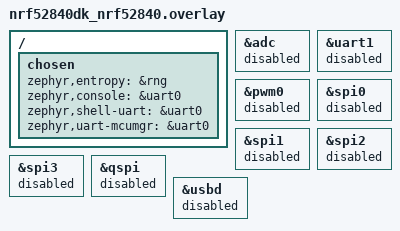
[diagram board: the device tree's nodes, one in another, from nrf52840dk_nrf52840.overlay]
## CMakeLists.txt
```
# SPDX-License-Identifier: Apache-2.0

cmake_minimum_required(VERSION 3.20.0)

find_package(Zephyr REQUIRED HINTS $ENV{ZEPHYR_BASE})

project(sensorConnect)

FILE(GLOB app_sources src/*c)
# APP START
target_sources(app PRIVATE ${app_sources})
```

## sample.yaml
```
sample:
  name: sensorConnect Sample
  description: Test OpenThread Command Line Interface.
tests:
  sample.basic.sensorConnect:
    tags: LED gpio
    filter: dt_enabled_alias_with_parent_compat("led0", "gpio-leds")
    depends_on: gpio
    harness: led
    integration_platforms:
      - frdm_k64f
  sample.openthread.cli:
    build_only: true
    platform_allow: >
      nrf5340dk_nrf5340_cpuapp nrf5340dk_nrf5340_cpuapp_ns nrf52840dk_nrf52840 nrf21540dk_nrf52840
    tags: ci_build
    extra_args: OVERLAY_CONFIG=overlay-ci.conf;overlay-multiprotocol.conf;overlay-tcp.conf
    integration_platforms:
      - nrf5340dk_nrf5340_cpuapp
      - nrf5340dk_nrf5340_cpuapp_ns
      - nrf52840dk_nrf52840
      - nrf21540dk_nrf52840
  sample.openthread.cli_nrf52833:
    build_only: true
    platform_allow: nrf52833dk_nrf52833
    tags: ci_build
    extra_args: OVERLAY_CONFIG=overlay-ci.conf
    integration_platforms:
      - nrf52833dk_nrf52833
  sample.openthread.cli.thread_1_1:
    build_only: true
    platform_allow: >
      nrf5340dk_nrf5340_cpuapp nrf5340dk_nrf5340_cpuapp_ns nrf52840dk_nrf52840 nrf21540dk_nrf52840
    tags: ci_build
    extra_args: >
      CONFIG_OPENTHREAD_THREAD_VERSION_1_1=y
      OVERLAY_CONFIG=overlay-ci.conf;overlay-multiprotocol.conf
    integration_platforms:
      - nrf5340dk_nrf5340_cpuapp
      - nrf5340dk_nrf5340_cpuapp_ns
      - nrf52840dk_nrf52840
      - nrf21540dk_nrf52840
  sample.openthread.cli.usb:
    build_only: true
    platform_allow: >
      nrf5340dk_nrf5340_cpuapp nrf5340dk_nrf5340_cpuapp_ns nrf52840dk_nrf52840
      nrf52840dongle_nrf52840 nrf21540dk_nrf52840
    tags: ci_build
    extra_args: >
      OVERLAY_CONFIG=overlay-usb.conf;overlay-ci.conf;overlay-multiprotocol.conf;overlay-tcp.conf
      DTC_OVERLAY_FILE=usb.overlay
    integration_platforms:
      - nrf5340dk_nrf5340_cpuapp
      - nrf5340dk_nrf5340_cpuapp_ns
      - nrf52840dk_nrf52840
      - nrf52840dongle_nrf52840
      - nrf21540dk_nrf52840
  sample.openthread.cli.low_power:
    build_only: true
    platform_allow: >
      nrf5340dk_nrf5340_cpuapp nrf5340dk_nrf5340_cpuapp_ns nrf52840dk_nrf52840 nrf21540dk_nrf52840
    tags: ci_build
    extra_args: OVERLAY_CONFIG=overlay-ci.conf;overlay-low_power.conf
                DTC_OVERLAY_FILE=low_power.overlay
    integration_platforms:
      - nrf5340dk_nrf5340_cpuapp
      - nrf5340dk_nrf5340_cpuapp_ns
      - nrf52840dk_nrf52840
      - nrf21540dk_nrf52840
  # Build integration regression protection.
  sample.nrf_security.openthread.integration:
    build_only: true
    extra_args: CONFIG_NRF_SECURITY=y
    platform_allow: nrf5340dk_nrf5340_cpuapp_ns nrf52840dk_nrf52840
    integration_platforms:
      - nrf5340dk_nrf5340_cpuapp_ns
      - nrf52840dk_nrf52840
```

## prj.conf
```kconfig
# nRF board library
CONFIG_DK_LIBRARY=y

# Enable OpenThread FTD features set
CONFIG_OPENTHREAD_NORDIC_LIBRARY_FTD=y

# L2 OpenThread enabling
CONFIG_NET_L2_OPENTHREAD=y

# Generic networking options
CONFIG_NETWORKING=y
CONFIG_MBEDTLS_SHA1_C=n
CONFIG_FPU=y

# Network parameter
CONFIG_OPENTHREAD_MANUAL_START=n
CONFIG_OPENTHREAD_NETWORK_NAME="WSN-00"
CONFIG_OPENTHREAD_PANID=10026
CONFIG_OPENTHREAD_XPANID="fb:02:00:00:ab:cd:00:00"
CONFIG_OPENTHREAD_NETWORKKEY="00:11:22:33:44:55:66:77:88:99:aa:bb:cc:dd:ee:ff"

CONFIG_OPENTHREAD_JOINER=y
CONFIG_OPENTHREAD_JOINER_AUTOSTART=y
CONFIG_OPENTHREAD_JOINER_PSKD="123456"

# Network shell
CONFIG_SHELL=y
CONFIG_OPENTHREAD_SHELL=y
CONFIG_SHELL_ARGC_MAX=26
CONFIG_SHELL_CMD_BUFF_SIZE=416

CONFIG_GPIO=y

# Enable OpenThread CoAP support API
CONFIG_OPENTHREAD_COAP=y

# Enable I2C
CONFIG_I2C=y

# Enable Console Print for Debugging
CONFIG_CBPRINTF_FP_SUPPORT=y

CONFIG_ENTROPY_GENERATOR=y
CONFIG_TEST_RANDOM_GENERATOR=y

# Enable FSM
CONFIG_SMF=y

# Enable Button Events
CONFIG_EVENTS=y

# Enable RTT logging in console
CONFIG_USE_SEGGER_RTT=y
CONFIG_LOG_BACKEND_RTT=y
CONFIG_LOG_BACKEND_UART=n
```

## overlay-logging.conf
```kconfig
#
# Copyright (c) 2021 Nordic Semiconductor
#
# SPDX-License-Identifier: LicenseRef-Nordic-5-Clause
# Enable Zephyr logging
CONFIG_LOG=y

# Use separate thread for logging
CONFIG_LOG_MODE_DEFERRED=y

# Increase max log level to informative
CONFIG_LOG_MAX_LEVEL=3

# Option for configuring log level in this sample
CONFIG_OT_COMMAND_LINE_INTERFACE_LOG_LEVEL_INF=y

# Enable net module logging
# CONFIG_NET_LOG=y
# Option for configuring log level in net config library
# CONFIG_NET_CONFIG_LOG_LEVEL_INF=y

# Option for configuring log level in Zephyr L2 logging
# CONFIG_OPENTHREAD_L2_DEBUG=y
# CONFIG_OPENTHREAD_L2_LOG_LEVEL_DBG=y
# CONFIG_OPENTHREAD_L2_DEBUG_DUMP_15_4=y
# CONFIG_OPENTHREAD_L2_DEBUG_DUMP_IPV6=y

# Enable OpenThread logging
CONFIG_OPENTHREAD_DEBUG=y
# Option for configuring log level in OpenThread
CONFIG_OPENTHREAD_LOG_LEVEL_INFO=y

# Enable RTT logging backend
CONFIG_USE_SEGGER_RTT=y
CONFIG_LOG_BACKEND_RTT=y

# Disable UART logging backend
# CONFIG_LOG_BACKEND_UART=n
CONFIG_SHELL_LOG_BACKEND=n
```

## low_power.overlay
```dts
/*
 * Copyright (c) 2023 Nordic Semiconductor ASA
 *
 * SPDX-License-Identifier: LicenseRef-Nordic-5-Clause
 */

&adc {
	status = "disabled";
};
&uart1 {
	status = "disabled";
};
&pwm0 {
	status = "disabled";
};

&spi0 {
	status = "disabled";
};
&spi1 {
	status = "disabled";
};
&spi2 {
	status = "disabled";
};
&spi3 {
	status = "disabled";
};
&usbd {
	status = "disabled";
};
```

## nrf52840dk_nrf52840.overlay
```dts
/ {
	chosen {
		zephyr,entropy = &rng;
		zephyr,console = &uart0;
		zephyr,shell-uart = &uart0;
		zephyr,uart-mcumgr = &uart0;
	};
};
&adc {
	status = "disabled";
};
&uart1 {
	status = "disabled";
};
&pwm0 {
	status = "disabled";
};
&spi0 {
	status = "disabled";
};
&spi1 {
	status = "disabled";
};
&spi2 {
	status = "disabled";
};
&spi3 {
	status = "disabled";
};
&qspi {
	status = "disabled";
};
&usbd {
	status = "disabled";
};
```

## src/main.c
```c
#include <dk_buttons_and_leds.h>
#include <zephyr/smf.h>
#include <zephyr/net/openthread.h>
#include <openthread/thread.h>
#include <openthread/coap.h>
#include <zephyr/drivers/gpio.h>

#include "sensor_functionality.h"

#define SLEEP_TIME_ONE 1
#define SLEEP_TIME_FIVE 5
#define SLEEP_TIME_TEN 10
#define SLEEP_TIME_THIRTY 30
#define SLEEP_TIME_SIXTY 60
#define SLEEP_TIME_THREE_MIN 180
#define NO_SLEEP_TIME 0

#define NO_ERROR 0

#define NO_BLINKING_LED 5

LOG_MODULE_REGISTER(main, LOG_LEVEL_INF);

/**
 * Boolean for printing read sensor values to the console
 * Change to true to enable
*/
static bool print_values_to_console = false;

/**
 * Modes for the Sensor Station
 * 
 * Measure: 		Start/stop periodic measurement
 * Config_period: 	Change the measurement period of the Sensor Station
 * Calibrate: 		Start/stop the selected calibration mode (only Co2 available)
 * 
*/
static enum sensor_station_mode { 
	MEASURE, 
	CONFIG_PERIOD, 
	CALIBRATE
} station_mode;

/* Variables used for managing modes, LEDs, Buttons and States of the SMF */
static bool mode_switch;

static bool btn2_pressed;
static bool btn3_pressed;
static bool btn4_pressed;

static bool run_calibration;
static bool run_per_measurement;
static bool run_frc;

static bool new_led_state;
static uint8_t blinking_led;

static struct k_work blinking_led_3sec_work;
static struct k_timer blinking_led_timer;

static bool show_idle_state;

/* Functions for Handling LEDs */

/**
 * set_blinking_led() - Sets the selected blinking_led to blinking ON/OFF.
*/
static void set_blinking_led() {

	k_timer_stop(&blinking_led_timer);
	switch(station_mode) {
		case CONFIG_PERIOD:
			switch (measure_period) {
				case SIXTY:
					blinking_led = DK_LED4;
					break;
				case THIRTY:
					blinking_led = DK_LED3;
					break;
				case FIVE:
				default:
					blinking_led = DK_LED1;
			}
			break;

		case CALIBRATE:
			switch (calib_mode) {
				case VOC:
					blinking_led = DK_LED2;
					break;
				case TEMP:
					blinking_led = DK_LED4;
					break;
				case CO2:
				default:
					blinking_led = DK_LED1;
			}
			break;
		case MEASURE:
		default:
			blinking_led = NO_BLINKING_LED; 		
	}
	if(blinking_led != NO_BLINKING_LED) {
		k_timer_start(&blinking_led_timer, K_MSEC(500), K_MSEC(500));
	}
}

/**
 * set_select_led() - Sets the selected blinking_led to blinking ON.
*/
static void set_select_led() {

	k_timer_stop(&blinking_led_timer);
	switch(station_mode) {
		case CONFIG_PERIOD:
			switch (measure_period) {
				case SIXTY:
					blinking_led = DK_LED4;
					break;
				case THIRTY:
					blinking_led = DK_LED3;
					break;
				case FIVE:
				default:
					blinking_led = DK_LED1;
			}
			break;

		case CALIBRATE:
			switch (calib_mode) {
				case VOC:
					blinking_led = DK_LED2;
					break;
				case TEMP:
					blinking_led = DK_LED4;
					break;
				case CO2:
				default:
					blinking_led = DK_LED1;
			}
			break;
		case MEASURE:
		default:
			blinking_led = DK_LED2; 		
	}
	
	dk_set_led_on(blinking_led);
}

/**
 * stop_blinking_led() - Sets the selected blinking_led to blinking OFF.
*/
static void stop_blinking_led() {

	k_timer_stop(&blinking_led_timer);
	dk_set_led_off(blinking_led);
}

static void activate_blinking_3_sec(struct k_work *item)
{
	ARG_UNUSED(item);

	set_blinking_led();
	k_sleep(K_SECONDS(SLEEP_TIME_FIVE));
	stop_blinking_led();
}

/* Expiry function of blinking_led_timer */
static void on_blinking_led_timer_expiry(struct k_timer *timer_id)
{
	static uint8_t val = 1;

	ARG_UNUSED(timer_id);

	dk_set_led(blinking_led, val);
	val = !val;
}

/* Stop function of blinking_led_timer */
static void on_blinking_led_timer_stop(struct k_timer *timer_id)
{
	ARG_UNUSED(timer_id);

	dk_set_led_off(blinking_led);
}


/* Button Handler */
static void on_button_changed(uint32_t button_state, uint32_t has_changed)
{
	uint32_t buttons = button_state & has_changed;
	
	if (buttons & DK_BTN1_MSK) {
		mode_switch = true;
	}
	if (buttons & DK_BTN2_MSK) {
		btn2_pressed = true;
	}
	if (buttons & DK_BTN3_MSK) {
		btn3_pressed = true;
	}
	if (buttons & DK_BTN4_MSK) {
		btn4_pressed = true;
	}

}

/* Forward declaration of helper function*/
static const char* station_mode_to_string(enum sensor_station_mode s_mode);
static bool sleep_interruptable(uint8_t sec, bool is_for_calibration);


/* CoAP functionality */
// VM-IP-ADDRESS
const char *serverIpAddr = "fd56:b1f:f132:2:0:0:10.80.2.239";

void coap_init(void);
void coap_send_data_response_cb(void *p_context, otMessage *p_message, const otMessageInfo *p_message_info, otError result);
void coap_send_data_request(char *message);


/* State Machine Framework */

int32_t smf_sleep_sec = NO_SLEEP_TIME;

/* Forward declaration of state table */
static const struct smf_state states[];

/* States */
enum state { 
	INIT, 
	IDLE, 
	START_MEASUREMENT, 
	STOP_MEASUREMENT, 
	READ_MEASUREMENT, 
	SEND_DATA, 
	START_CALIB_MEASUREMENT, 
	CALIB_READY, 
	FRC
};

struct s_object {
	/* This must be first */
	struct smf_ctx ctx;
	/* Error Value */
	int16_t error;
} s_obj;

/* State INIT */
static void init_run(void *o){
	printk("State: INIT\n");

	blinking_led = DK_LED1;
	k_timer_start(&blinking_led_timer, K_MSEC(500), K_MSEC(500));
	
	struct s_object *s = (struct s_object *)o;
	s->error = NO_ERROR;


	/* Init Settings for Sensor Station */
	station_mode = MEASURE;
	mode_switch = false;
	btn2_pressed = false;
	btn3_pressed = false;
	btn4_pressed = false;

	measure_period = FIVE;
	calib_mode = CO2;

	run_per_measurement = false;
	run_calibration = false;
	run_frc = false;

	/* Init Sensor Measuring */
	sensirion_i2c_hal_get();
	clean_up_sensor_states(&(s->error));
	if(s->error) {
		printk("Error executing clean_up_sensor_states(): %i\n", s->error);
		smf_set_state(SMF_CTX(&s_obj), &states[IDLE]);
		return;
	}

	/* Init CoAP */
	coap_init();

	k_timer_stop(&blinking_led_timer);
	smf_sleep_sec = SLEEP_TIME_FIVE;
	new_led_state = true;
	show_idle_state = true;
	smf_set_state(SMF_CTX(&s_obj), &states[IDLE]);
}


/* State IDLE */
static void idle_entry(void *o) {
	if(show_idle_state) {
		printk("State: IDLE\tMode: %s\n", station_mode_to_string(station_mode));
		show_idle_state = false;
		}
}

static void idle_run(void *o){

	struct s_object *s = (struct s_object *)o;
	s->error = NO_ERROR;
	
	switch(station_mode) {

		/* Mode CONFIG_PERIOD */
		case CONFIG_PERIOD:
			dk_set_led_on(DK_LED2);
			if(btn2_pressed) {
				measure_period = FIVE;
				printk("measure_period Change: FIVE\n");
				new_led_state = true;
				btn2_pressed = false;
			}
			if(btn3_pressed) {
				measure_period = THIRTY;
				printk("measure_period Change: THIRTY\n");
				new_led_state = true;
				btn3_pressed = false;
			}
			if(btn4_pressed) {
				measure_period = SIXTY;
				printk("measure_period Change: SIXTY\n");
				new_led_state = true;
				btn4_pressed = false;
			}
			if(new_led_state) {
				dk_set_leds(DK_NO_LEDS_MSK);
				set_blinking_led();
				new_led_state = false;
			}
			break;

		/* Mode CALIBRATE */
		case CALIBRATE:
			dk_set_led_on(DK_LED3);
			if(btn2_pressed) {
				if(calib_mode == CO2 && run_calibration) {
					smf_set_state(SMF_CTX(&s_obj), &states[START_CALIB_MEASUREMENT]);
					smf_sleep_sec = SLEEP_TIME_ONE;
					btn2_pressed = false;
					new_led_state = true;
					return;
				}
				else if(calib_mode == CO2) {
					printk("User Select CO2 Calibration\n");
					run_calibration = true;
					set_select_led();
				}
				else {
					printk("calib_mode Change: CO2\n");
					calib_mode = CO2;
					run_calibration = false;
					new_led_state = true;
				}
				btn2_pressed = false;
			}
			if(btn3_pressed) {
				if(calib_mode == VOC && run_calibration) {
					smf_set_state(SMF_CTX(&s_obj), &states[START_CALIB_MEASUREMENT]);
					smf_sleep_sec = SLEEP_TIME_ONE;
					btn3_pressed = false;
					new_led_state = true;
					return;
				}
				else if(calib_mode == VOC) {
					printk("User Select VOC Calibration\n");
					run_calibration = true;
					set_select_led();
				}
				else {
					printk("calib_mode Change: VOC\n");
					calib_mode = VOC;
					run_calibration = false;
					new_led_state = true;
				}
				btn3_pressed = false;
			}
			if(btn4_pressed) {
				if(calib_mode == TEMP && run_calibration) {
					smf_set_state(SMF_CTX(&s_obj), &states[START_CALIB_MEASUREMENT]);
					smf_sleep_sec = SLEEP_TIME_ONE;
					btn4_pressed = false;
					new_led_state = true;
					return;
				}
				else if(calib_mode == TEMP) {
					printk("User Select TEMP Calibration\n");
					run_calibration = true;
					set_select_led();
				
				}
				else {
					printk("calib_mode Change: TEMP\n");
					calib_mode = TEMP;
					run_calibration = false;
					new_led_state = true;
				}
				btn4_pressed = false;
			}
			if(new_led_state) {
				dk_set_leds(DK_NO_LEDS_MSK);
				set_blinking_led();
				new_led_state = false;
			}
			break;


		/* Mode MEASURE */
		case MEASURE:
		default:
			dk_set_led_on(DK_LED1); 		
			if(btn2_pressed) {
				if(run_per_measurement) {
					smf_set_state(SMF_CTX(&s_obj), &states[START_MEASUREMENT]);
					smf_sleep_sec = SLEEP_TIME_ONE;
					btn2_pressed = false;
					return;
				}
				else {
					printk("User Select Start Measurement\n");
					run_per_measurement = true;
					set_select_led(blinking_led);
				}
				btn2_pressed = false;
			}
			if(btn3_pressed) {
				// do nothing
				run_per_measurement = false;
				btn3_pressed = false;
				new_led_state = true;
			}
			if(btn4_pressed) {
				// do nothing
				run_per_measurement = false;
				btn4_pressed = false;
				new_led_state = true;
			}
			if(new_led_state) {
				dk_set_leds(DK_NO_LEDS_MSK);
				set_blinking_led();
				new_led_state = false;
			}
			break;
	}
	
	smf_sleep_sec = NO_SLEEP_TIME;
	smf_set_state(SMF_CTX(&s_obj), &states[IDLE]);
}

/* State START_MEASUREMENT */
static void start_measurement_run(void *o){
	printk("State: START_MEASUREMENT\tmeasure_period: %s\n", measure_period_to_string(measure_period));

	struct s_object *s = (struct s_object *)o;
	s->error = NO_ERROR;

	dk_set_leds(DK_NO_LEDS_MSK);
	stop_blinking_led();
	blinking_led = DK_LED1;
	
	/* Start periodic measurement */
	start_periodic_measurement(&(s->error), true);
	if(s->error) {
		printk("Error executing start_periodic_measurement()\n: %i", s->error);
		return;
	}

	if(sleep_interruptable(SLEEP_TIME_TEN, false)) {
		smf_set_state(SMF_CTX(&s_obj), &states[STOP_MEASUREMENT]);
		smf_sleep_sec = NO_SLEEP_TIME;
		return;
	}

	smf_sleep_sec = NO_SLEEP_TIME;
	smf_set_state(SMF_CTX(&s_obj), &states[READ_MEASUREMENT]);
}

/* State STOP_MEASUREMENT */
static void stop_measurement_run(void *o){
	printk("State: STOP_MEASUREMENT\n");
	
	struct s_object *s = (struct s_object *)o;
	s->error = NO_ERROR;

	stop_blinking_led();

	/* Stop periodic measurement */
	stop_periodic_measurement(&(s->error));
	if(s->error) {
		printk("Error executing stop_periodic_measurement(): %i\n", s->error);
		return;
	}

	dk_set_leds(DK_ALL_LEDS_MSK);
	
	run_calibration = false;
	run_per_measurement = false;
	run_frc = false;

	new_led_state = true;
	smf_sleep_sec = NO_SLEEP_TIME;
	
	show_idle_state = true;
	smf_set_state(SMF_CTX(&s_obj), &states[IDLE]);
}

/* State READ_MEASUREMENT */
static void read_measurement_run(void *o){
	printk("State: READ_MEASUREMENT\n");

	struct s_object *s = (struct s_object *)o;
	s->error = NO_ERROR;

	stop_blinking_led();

	/* for measure_period = SIXTY, a single shot is performed */
	if(measure_period == SIXTY) {
		perform_single_measurement_scd41(&(s->error));
		if(s->error) {
			printk("Error executing perform_single_measurement_scd41(): %i\n", s->error);
			//return;
		}
	}

	/* Read the Measurement */
	read_measurement(&(s->error));
	if(s->error) {
		printk("Error executing read_measurement(): %i\n", s->error);
		//return;
	}

	/* Invoke console print if print_values_to_console is enabled */
	if(print_values_to_console) {
		print_measurement_to_console();
	}

	smf_sleep_sec = NO_SLEEP_TIME;
	smf_set_state(SMF_CTX(&s_obj), &states[SEND_DATA]);
}

/* State SEND_DATA */
static void send_data_run(void *o){
	printk("State: SEND_DATA\n");

	struct s_object *s = (struct s_object *)o;
	s->error = NO_ERROR;
	
	// Use shared data for CoAP communication
	char* my_sensor_data;
	my_sensor_data = create_coap_message();
	coap_send_data_request(my_sensor_data);
	free(my_sensor_data);

	/** 
	 * Station sleeps for measure_period for another read/send-cycle to start.
	 * If the stop button (Button 4) or the Button for changing the
	 * Sensor Station mode (Button 1) is pressed while sleeping, stop measuring and
	 * return to idle.
	*/
	switch(measure_period) {
		case FIVE: 
			if(sleep_interruptable(SLEEP_TIME_FIVE, false)) {
				smf_set_state(SMF_CTX(&s_obj), &states[STOP_MEASUREMENT]);
				smf_sleep_sec = NO_SLEEP_TIME;
				return;
			}
			break;
		case THIRTY:
			if(sleep_interruptable(SLEEP_TIME_THIRTY, false)) {
				smf_set_state(SMF_CTX(&s_obj), &states[STOP_MEASUREMENT]);
				smf_sleep_sec = NO_SLEEP_TIME;
				return;
			}
			break;
		case SIXTY:
			if(sleep_interruptable(SLEEP_TIME_SIXTY, false)) {
				smf_set_state(SMF_CTX(&s_obj), &states[STOP_MEASUREMENT]);
				smf_sleep_sec = NO_SLEEP_TIME;
				return;
			}
			break;
	}
	smf_sleep_sec = NO_SLEEP_TIME;
	smf_set_state(SMF_CTX(&s_obj), &states[READ_MEASUREMENT]);
}

/* State START_CALIB_MEASUREMENT */
static void start_calib_measurement_run(void *o){
	printk("State: START_CALIB_MEASUREMEN, calib_mode: %s, measure_period: %s\n", calib_mode_to_string(calib_mode), measure_period_to_string(measure_period));
	struct s_object *s = (struct s_object *)o;
	s->error = NO_ERROR;

	set_select_led();

	switch(calib_mode) {
		case CO2:
			/* measure CO2 for 3 Minutes, interruptable with Button 1 (change mode) or 4 (stop) */
			start_periodic_measurement(&(s->error), false);
			if(s->error) {
				printk("Error executing start_periodic_measurement(): %i\n", s->error);
				return;
			}

			if(sleep_interruptable(SLEEP_TIME_THREE_MIN, true)) {
				smf_set_state(SMF_CTX(&s_obj), &states[STOP_MEASUREMENT]);
				smf_sleep_sec = NO_SLEEP_TIME;
				return;
			}

			stop_periodic_measurement(&(s->error));
			if(s->error) {
				printk("Error executing start_periodic_measurement(): %i\n", s->error);
				return;
			}
			stop_blinking_led();
			smf_sleep_sec = SLEEP_TIME_ONE;
			break;
		case VOC:
			/* Not implemented, thus disabled */
			break;
		case TEMP:
			/* Not implemented, thus disabled */
			break;
	}
	
	show_idle_state = true;
	smf_set_state(SMF_CTX(&s_obj), &states[CALIB_READY]);
}

/* State CALIB_READY */
static void calib_ready_run(void *o){
	if(show_idle_state){
		printk("State: CALIB_READY\n");
		show_idle_state = false;
	}

	struct s_object *s = (struct s_object *)o;
	s->error = NO_ERROR;
	set_blinking_led();
	switch(calib_mode) {
		case CO2:
			if(btn2_pressed) {
				if(run_frc) {
					smf_set_state(SMF_CTX(&s_obj), &states[FRC]);
					smf_sleep_sec = NO_SLEEP_TIME;
					btn2_pressed = false;
					return;
				}
				run_frc = true;
				set_select_led();
				break;
			}
			break;
		case VOC:
			/* Not implemented, thus disabled */
			break;
		case TEMP:
		default:
			/* Not implemented, thus disabled */
	}
	
	smf_sleep_sec = NO_SLEEP_TIME;
	smf_set_state(SMF_CTX(&s_obj), &states[CALIB_READY]);
}

/* State FRC */
static void frc_run(void *o){
	printk("State: FRC\n");
	
	struct s_object *s = (struct s_object *)o;
	s->error = NO_ERROR;
	stop_blinking_led();

	switch(calib_mode) {
		case CO2:
			forced_co2_recalibration(&(s->error));
			break;
		case VOC:
			/* Not implemented, thus disabled */
			break;
		case TEMP:
		default:
			/* Not implemented, thus disabled */
	}
	
	smf_sleep_sec = SLEEP_TIME_ONE;
	run_frc = false;
	new_led_state = true;
	
	show_idle_state = true;
	smf_set_state(SMF_CTX(&s_obj), &states[IDLE]);
}

/* Populate SMF state table */
static const struct smf_state states[] = {
	[INIT] = SMF_CREATE_STATE(NULL, init_run, NULL),
	[IDLE] = SMF_CREATE_STATE(idle_entry, idle_run, NULL),
	[START_MEASUREMENT] = SMF_CREATE_STATE(NULL, start_measurement_run, NULL),
	[STOP_MEASUREMENT] = SMF_CREATE_STATE(NULL, stop_measurement_run, NULL),
	[READ_MEASUREMENT] = SMF_CREATE_STATE(NULL, read_measurement_run, NULL),
	[SEND_DATA] = SMF_CREATE_STATE(NULL, send_data_run, NULL),
	[START_CALIB_MEASUREMENT] = SMF_CREATE_STATE(NULL, start_calib_measurement_run, NULL),
	[CALIB_READY] = SMF_CREATE_STATE(NULL, calib_ready_run, NULL),
	[FRC] = SMF_CREATE_STATE(NULL, frc_run, NULL)
};

/* main function */
int main(void)
{
	int32_t ret;

	/* Initialize timers on work queue for LEDs */
	k_timer_init(&blinking_led_timer, on_blinking_led_timer_expiry, on_blinking_led_timer_stop);
	k_work_init(&blinking_led_3sec_work, activate_blinking_3_sec);

	/* Initialize LEDs and Buttons */
	ret = dk_leds_init();
	if (ret) {
		printk("Could not initialize leds, err code: %d\n", ret);
		goto end;
	}

	ret = dk_buttons_init(on_button_changed);
	if (ret) {
		printk("Cannot init buttons (error: %d)\n", ret);
		goto end;
	}

	/* Set init SMF state */
	smf_set_initial(SMF_CTX(&s_obj), &states[INIT]);
	

	while (1) {
		/* run selected SMF state */
		ret = smf_run_state(SMF_CTX(&s_obj));
		if(ret) {
			printk("SMF Run State Error: %d\n", ret);
			smf_set_initial(SMF_CTX(&s_obj), &states[INIT]);
			smf_sleep_sec = SLEEP_TIME_ONE;
			continue;
		}

		/* End Application if an error occured during a state*/
		if(s_obj.error) {
			printk("Error Inside Run State: %d\n", ret);
			smf_set_state(SMF_CTX(&s_obj), &states[STOP_MEASUREMENT]);
			ret = smf_run_state(SMF_CTX(&s_obj));
			if(ret) {
				printk("SMF Run State Error: %d\n", ret);
			}
			goto end;
		}
		
		/* Stop, if the stop button (Button 4) is pressed while Sensor Station is running not in idle mode*/
		if(btn4_pressed && (run_calibration || run_per_measurement|| run_frc)) {
			smf_set_state(SMF_CTX(&s_obj), &states[STOP_MEASUREMENT]);
			ret = smf_run_state(SMF_CTX(&s_obj));
			smf_sleep_sec = NO_SLEEP_TIME;
			btn4_pressed = false;
		}

		/* Change Mode if Button 1 is pressed */
		if(mode_switch) {
			switch(station_mode) {
				case CONFIG_PERIOD: 
					station_mode = CALIBRATE;
					smf_sleep_sec = NO_SLEEP_TIME;
					smf_set_state(SMF_CTX(&s_obj), &states[IDLE]);
					break;

				case CALIBRATE: 	
					station_mode = MEASURE;
					smf_sleep_sec = NO_SLEEP_TIME;
					(run_calibration || run_frc) ? smf_set_state(SMF_CTX(&s_obj), &states[STOP_MEASUREMENT])
									: smf_set_state(SMF_CTX(&s_obj), &states[IDLE]);
					break;

				case MEASURE:
				default:	 		
					station_mode = CONFIG_PERIOD;
					smf_sleep_sec = NO_SLEEP_TIME;
					run_per_measurement ? smf_set_state(SMF_CTX(&s_obj), &states[STOP_MEASUREMENT])
										: smf_set_state(SMF_CTX(&s_obj), &states[IDLE]);
					new_led_state = true;
					break;
			};
			mode_switch = false;
			new_led_state = true;
			show_idle_state = true;
		}

		k_sleep(K_SECONDS(smf_sleep_sec));
	}
end:
	return 0;
}

/**
 * sleep_interruptable() - Helper method for interruptable sleep of a  SMF state
 * 
 * This method lets a SMF state sleeping, while checking every second, if
 * Button 1 or 4 have been pressed. If so, it stops the waiting time.
 * 
 * @param sec seconds for the SMF state to sleep
 * @param is_for_calibration when set true and the measure_period is SIXTY, the function
 * performs a single shot measurement every 60 seconds.
 * @returns false, if no interrupt happened, true otherwise.
*/
static bool sleep_interruptable(uint8_t sec, bool is_for_calibration) {

	for(uint8_t i = 0; i < sec; i++) {
		k_sleep(K_SECONDS(1));
		if(is_for_calibration && measure_period == SIXTY && i % 60 == 0) {
			/* for SIXTY second period, a single shot is performed */
			perform_single_measurement_scd41(&s_obj.error);
			if(s_obj.error) {
				printk("Error executing perform_single_measurement_scd41(): %i\n", s_obj.error);
				//return;
			}
		}
	
		if(btn4_pressed || mode_switch) {
			btn4_pressed = false;
			mode_switch = false;
			return true;
		}
	}
	return false;
}

/**
 * station_mode_to_string() - Helper function to change the enum sensor_station_mode to a string.
 * 
 * @param s_mode the current mode of the Sensor Station
 * @returns the String representation of the enum
*/
static const char* station_mode_to_string(enum sensor_station_mode s_mode) {
    switch (s_mode) {
        case MEASURE:
            return "MEASURE";
        case CONFIG_PERIOD:
            return "CONFIG_PERIOD";
        case CALIBRATE:
            return "CALIBRATE";
        default:
            return "Unknown";
    }
}

/* CoAP functions */

/* Initializes the CoAP functionality */
void coap_init(void)
{
	otInstance *p_instance = openthread_get_default_instance();
	otError error = otCoapStart(p_instance, OT_DEFAULT_COAP_PORT);
	if (error != OT_ERROR_NONE)
	{
		printk("Failed to start Coap: %d\n", error);
	}
}

/* Callback function for CoAP Server response handling */
void coap_send_data_response_cb(void *p_context, otMessage *p_message, const otMessageInfo *p_message_info, otError result)
{
	if (result == OT_ERROR_NONE)
	{
		printk("CoAP Response: Delivery confirmed.\n");
	}
	else
	{
		printk("CoAP Response: Delivery not confirmed: %d\n", result);
	}
}

/* Sends a message to the CoAP Server */
void coap_send_data_request(char *message)
{
	otError error = OT_ERROR_NONE;
	otMessage *myMessage;
	otMessageInfo myMessageInfo;
	otInstance *myInstance = openthread_get_default_instance();
	const otMeshLocalPrefix *ml_prefix = otThreadGetMeshLocalPrefix(myInstance);
	uint8_t serverInterfaceID[8] = {0x00, 0x00, 0x00, 0x00, 0x00, 0x00, 0x00, 0x01};

	const char *myTemperatureJson = message;
	do
	{
		myMessage = otCoapNewMessage(myInstance, NULL);
		if (myMessage == NULL)
		{
			printk("Failed to allocate message for CoAP Request\n");
			return;
		}
		otCoapMessageInit(myMessage, OT_COAP_TYPE_CONFIRMABLE, OT_COAP_CODE_PUT);
		error = otCoapMessageAppendUriPathOptions(myMessage, "sensors");
		if (error != OT_ERROR_NONE)
		{
			break;
		}
		error = otCoapMessageAppendContentFormatOption(myMessage, OT_COAP_OPTION_CONTENT_FORMAT_JSON);
		if (error != OT_ERROR_NONE)
		{
			break;
		}
		error = otCoapMessageSetPayloadMarker(myMessage);
		if (error != OT_ERROR_NONE)
		{
			break;
		}
		error = otMessageAppend(myMessage, myTemperatureJson, strlen(myTemperatureJson));
		if (error != OT_ERROR_NONE)
		{
			break;
		}
		memset(&myMessageInfo, 0, sizeof(myMessageInfo));
		memcpy(&myMessageInfo.mPeerAddr.mFields.m8[0], ml_prefix, 8);
		memcpy(&myMessageInfo.mPeerAddr.mFields.m8[8], serverInterfaceID, 8);
		myMessageInfo.mPeerPort = OT_DEFAULT_COAP_PORT;
		error = otIp6AddressFromString(serverIpAddr, &myMessageInfo.mPeerAddr);
		error = otCoapSendRequest(myInstance, myMessage, &myMessageInfo, coap_send_data_response_cb, NULL);
	} while (false);

	if (error != OT_ERROR_NONE)
	{
		printk("Failed to send CoAP Request: %d\n", error);
		otMessageFree(myMessage);
	}
	else
	{
		printk("CoAP data send.\n");
	}
}
```

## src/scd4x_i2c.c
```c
/*
 * THIS FILE IS AUTOMATICALLY GENERATED AND MUST NOT BE EDITED MANUALLY!
 *
 * I2C-Generator: 0.2.0
 * Yaml Version: 0.1.0
 * Template Version: 0.2.1
 */

#include "scd4x_i2c.h"
#include "sensirion_common.h"
#include "sensirion_i2c.h"
#include "sensirion_i2c_hal.h"

#define SCD4X_I2C_ADDRESS 98

int16_t scd4x_start_periodic_measurement() {
    int16_t error;
    uint8_t buffer[2];
    uint16_t offset = 0;
    offset = sensirion_i2c_add_command_to_buffer(&buffer[0], offset, 0x21B1);

    error = sensirion_i2c_write_data(SCD4X_I2C_ADDRESS, &buffer[0], offset);
    if (error) {
        return error;
    }
    sensirion_i2c_hal_sleep_usec(1000);
    return NO_ERROR;
}

int16_t scd4x_read_measurement_ticks(uint16_t* co2, uint16_t* temperature,
                                     uint16_t* humidity) {
    int16_t error;
    uint8_t buffer[9];
    uint16_t offset = 0;
    offset = sensirion_i2c_add_command_to_buffer(&buffer[0], offset, 0xEC05);

    error = sensirion_i2c_write_data(SCD4X_I2C_ADDRESS, &buffer[0], offset);
    if (error) {
        return error;
    }

    sensirion_i2c_hal_sleep_usec(1000);

    error = sensirion_i2c_read_data_inplace(SCD4X_I2C_ADDRESS, &buffer[0], 6);
    if (error) {
        return error;
    }
    *co2 = sensirion_common_bytes_to_uint16_t(&buffer[0]);
    *temperature = sensirion_common_bytes_to_uint16_t(&buffer[2]);
    *humidity = sensirion_common_bytes_to_uint16_t(&buffer[4]);
    return NO_ERROR;
}

int16_t scd4x_read_measurement(uint16_t* co2, int32_t* temperature_m_deg_c,
                               int32_t* humidity_m_percent_rh) {
    int16_t error;
    uint16_t temperature;
    uint16_t humidity;

    error = scd4x_read_measurement_ticks(co2, &temperature, &humidity);
    if (error) {
        return error;
    }
    *temperature_m_deg_c = ((21875 * (int32_t)temperature) >> 13) - 45000;
    *humidity_m_percent_rh = ((12500 * (int32_t)humidity) >> 13);
    return NO_ERROR;
}

int16_t scd4x_stop_periodic_measurement() {
    int16_t error;
    uint8_t buffer[2];
    uint16_t offset = 0;
    offset = sensirion_i2c_add_command_to_buffer(&buffer[0], offset, 0x3F86);

    error = sensirion_i2c_write_data(SCD4X_I2C_ADDRESS, &buffer[0], offset);
    if (error) {
        return error;
    }
    sensirion_i2c_hal_sleep_usec(500000);
    return NO_ERROR;
}

int16_t scd4x_get_temperature_offset_ticks(uint16_t* t_offset) {
    int16_t error;
    uint8_t buffer[3];
    uint16_t offset = 0;
    offset = sensirion_i2c_add_command_to_buffer(&buffer[0], offset, 0x2318);

    error = sensirion_i2c_write_data(SCD4X_I2C_ADDRESS, &buffer[0], offset);
    if (error) {
        return error;
    }

    sensirion_i2c_hal_sleep_usec(1000);

    error = sensirion_i2c_read_data_inplace(SCD4X_I2C_ADDRESS, &buffer[0], 2);
    if (error) {
        return error;
    }
    *t_offset = sensirion_common_bytes_to_uint16_t(&buffer[0]);
    return NO_ERROR;
}

int16_t scd4x_get_temperature_offset(int32_t* t_offset_m_deg_c) {
    int16_t error;
    uint16_t t_offset;

    error = scd4x_get_temperature_offset_ticks(&t_offset);
    if (error) {
        return error;
    }
    *t_offset_m_deg_c = ((21875 * (int32_t)t_offset) >> 13);
    return NO_ERROR;
}

int16_t scd4x_set_temperature_offset_ticks(uint16_t t_offset) {
    int16_t error;
    uint8_t buffer[5];
    uint16_t offset = 0;
    offset = sensirion_i2c_add_command_to_buffer(&buffer[0], offset, 0x241D);

    offset = sensirion_i2c_add_uint16_t_to_buffer(&buffer[0], offset, t_offset);

    error = sensirion_i2c_write_data(SCD4X_I2C_ADDRESS, &buffer[0], offset);
    if (error) {
        return error;
    }
    sensirion_i2c_hal_sleep_usec(1000);
    return NO_ERROR;
}

int16_t scd4x_set_temperature_offset(int32_t t_offset_m_deg_c) {
    uint16_t t_offset = (uint16_t)((t_offset_m_deg_c * 12271) >> 15);
    return scd4x_set_temperature_offset_ticks(t_offset);
}

int16_t scd4x_get_sensor_altitude(uint16_t* sensor_altitude) {
    int16_t error;
    uint8_t buffer[3];
    uint16_t offset = 0;
    offset = sensirion_i2c_add_command_to_buffer(&buffer[0], offset, 0x2322);

    error = sensirion_i2c_write_data(SCD4X_I2C_ADDRESS, &buffer[0], offset);
    if (error) {
        return error;
    }

    sensirion_i2c_hal_sleep_usec(1000);

    error = sensirion_i2c_read_data_inplace(SCD4X_I2C_ADDRESS, &buffer[0], 2);
    if (error) {
        return error;
    }
    *sensor_altitude = sensirion_common_bytes_to_uint16_t(&buffer[0]);
    return NO_ERROR;
}

int16_t scd4x_set_sensor_altitude(uint16_t sensor_altitude) {
    int16_t error;
    uint8_t buffer[5];
    uint16_t offset = 0;
    offset = sensirion_i2c_add_command_to_buffer(&buffer[0], offset, 0x2427);

    offset = sensirion_i2c_add_uint16_t_to_buffer(&buffer[0], offset,
                                                  sensor_altitude);

    error = sensirion_i2c_write_data(SCD4X_I2C_ADDRESS, &buffer[0], offset);
    if (error) {
        return error;
    }
    sensirion_i2c_hal_sleep_usec(1000);
    return NO_ERROR;
}

int16_t scd4x_set_ambient_pressure(uint16_t ambient_pressure) {
    int16_t error;
    uint8_t buffer[5];
    uint16_t offset = 0;
    offset = sensirion_i2c_add_command_to_buffer(&buffer[0], offset, 0xE000);

    offset = sensirion_i2c_add_uint16_t_to_buffer(&buffer[0], offset,
                                                  ambient_pressure);

    error = sensirion_i2c_write_data(SCD4X_I2C_ADDRESS, &buffer[0], offset);
    if (error) {
        return error;
    }
    sensirion_i2c_hal_sleep_usec(1000);
    return NO_ERROR;
}

int16_t scd4x_perform_forced_recalibration(uint16_t target_co2_concentration,
                                           uint16_t* frc_correction) {
    int16_t error;
    uint8_t buffer[5];
    uint16_t offset = 0;
    offset = sensirion_i2c_add_command_to_buffer(&buffer[0], offset, 0x362F);

    offset = sensirion_i2c_add_uint16_t_to_buffer(&buffer[0], offset,
                                                  target_co2_concentration);

    error = sensirion_i2c_write_data(SCD4X_I2C_ADDRESS, &buffer[0], offset);
    if (error) {
        return error;
    }

    sensirion_i2c_hal_sleep_usec(400000);

    error = sensirion_i2c_read_data_inplace(SCD4X_I2C_ADDRESS, &buffer[0], 2);
    if (error) {
        return error;
    }
    *frc_correction = sensirion_common_bytes_to_uint16_t(&buffer[0]);
    return NO_ERROR;
}

int16_t scd4x_get_automatic_self_calibration(uint16_t* asc_enabled) {
    int16_t error;
    uint8_t buffer[3];
    uint16_t offset = 0;
    offset = sensirion_i2c_add_command_to_buffer(&buffer[0], offset, 0x2313);

    error = sensirion_i2c_write_data(SCD4X_I2C_ADDRESS, &buffer[0], offset);
    if (error) {
        return error;
    }

    sensirion_i2c_hal_sleep_usec(1000);

    error = sensirion_i2c_read_data_inplace(SCD4X_I2C_ADDRESS, &buffer[0], 2);
    if (error) {
        return error;
    }
    *asc_enabled = sensirion_common_bytes_to_uint16_t(&buffer[0]);
    return NO_ERROR;
}

int16_t scd4x_set_automatic_self_calibration(uint16_t asc_enabled) {
    int16_t error;
    uint8_t buffer[5];
    uint16_t offset = 0;
    offset = sensirion_i2c_add_command_to_buffer(&buffer[0], offset, 0x2416);

    offset =
        sensirion_i2c_add_uint16_t_to_buffer(&buffer[0], offset, asc_enabled);

    error = sensirion_i2c_write_data(SCD4X_I2C_ADDRESS, &buffer[0], offset);
    if (error) {
        return error;
    }
    sensirion_i2c_hal_sleep_usec(1000);
    return NO_ERROR;
}

int16_t scd4x_start_low_power_periodic_measurement() {
    uint8_t buffer[2];
    uint16_t offset = 0;
    offset = sensirion_i2c_add_command_to_buffer(&buffer[0], offset, 0x21AC);

    return sensirion_i2c_write_data(SCD4X_I2C_ADDRESS, &buffer[0], offset);
}

int16_t scd4x_get_data_ready_flag(bool* data_ready_flag) {
    int16_t error;
    uint8_t buffer[3];
    uint16_t offset = 0;
    uint16_t local_data_ready = 0;
    offset = sensirion_i2c_add_command_to_buffer(&buffer[0], offset, 0xE4B8);

    error = sensirion_i2c_write_data(SCD4X_I2C_ADDRESS, &buffer[0], offset);
    if (error) {
        return error;
    }

    sensirion_i2c_hal_sleep_usec(1000);

    error = sensirion_i2c_read_data_inplace(SCD4X_I2C_ADDRESS, &buffer[0], 2);
    if (error) {
        return error;
    }
    local_data_ready = sensirion_common_bytes_to_uint16_t(&buffer[0]);
    *data_ready_flag = (local_data_ready & 0x07FF) != 0;
    return NO_ERROR;
}

int16_t scd4x_persist_settings() {
    int16_t error;
    uint8_t buffer[2];
    uint16_t offset = 0;
    offset = sensirion_i2c_add_command_to_buffer(&buffer[0], offset, 0x3615);

    error = sensirion_i2c_write_data(SCD4X_I2C_ADDRESS, &buffer[0], offset);
    if (error) {
        return error;
    }
    sensirion_i2c_hal_sleep_usec(800000);
    return NO_ERROR;
}

int16_t scd4x_get_serial_number(uint16_t* serial_0, uint16_t* serial_1,
                                uint16_t* serial_2) {
    int16_t error;
    uint8_t buffer[9];
    uint16_t offset = 0;
    offset = sensirion_i2c_add_command_to_buffer(&buffer[0], offset, 0x3682);

    error = sensirion_i2c_write_data(SCD4X_I2C_ADDRESS, &buffer[0], offset);
    if (error) {
        return error;
    }

    sensirion_i2c_hal_sleep_usec(1000);

    error = sensirion_i2c_read_data_inplace(SCD4X_I2C_ADDRESS, &buffer[0], 6);
    if (error) {
        return error;
    }
    *serial_0 = sensirion_common_bytes_to_uint16_t(&buffer[0]);
    *serial_1 = sensirion_common_bytes_to_uint16_t(&buffer[2]);
    *serial_2 = sensirion_common_bytes_to_uint16_t(&buffer[4]);
    return NO_ERROR;
}

int16_t scd4x_perform_self_test(uint16_t* sensor_status) {
    int16_t error;
    uint8_t buffer[3];
    uint16_t offset = 0;
    offset = sensirion_i2c_add_command_to_buffer(&buffer[0], offset, 0x3639);

    error = sensirion_i2c_write_data(SCD4X_I2C_ADDRESS, &buffer[0], offset);
    if (error) {
        return error;
    }

    sensirion_i2c_hal_sleep_usec(10000000);

    error = sensirion_i2c_read_data_inplace(SCD4X_I2C_ADDRESS, &buffer[0], 2);
    if (error) {
        return error;
    }
    *sensor_status = sensirion_common_bytes_to_uint16_t(&buffer[0]);
    return NO_ERROR;
}

int16_t scd4x_perform_factory_reset() {
    int16_t error;
    uint8_t buffer[2];
    uint16_t offset = 0;
    offset = sensirion_i2c_add_command_to_buffer(&buffer[0], offset, 0x3632);

    error = sensirion_i2c_write_data(SCD4X_I2C_ADDRESS, &buffer[0], offset);
    if (error) {
        return error;
    }
    sensirion_i2c_hal_sleep_usec(800000);
    return NO_ERROR;
}

int16_t scd4x_reinit() {
    int16_t error;
    uint8_t buffer[2];
    uint16_t offset = 0;
    offset = sensirion_i2c_add_command_to_buffer(&buffer[0], offset, 0x3646);

    error = sensirion_i2c_write_data(SCD4X_I2C_ADDRESS, &buffer[0], offset);
    if (error) {
        return error;
    }
    sensirion_i2c_hal_sleep_usec(20000);
    return NO_ERROR;
}

int16_t scd4x_measure_single_shot() {
    int16_t error;
    uint8_t buffer[2];
    uint16_t offset = 0;
    offset = sensirion_i2c_add_command_to_buffer(&buffer[0], offset, 0x219D);

    error = sensirion_i2c_write_data(SCD4X_I2C_ADDRESS, &buffer[0], offset);
    if (error) {
        return error;
    }
    sensirion_i2c_hal_sleep_usec(5000000);
    return NO_ERROR;
}

int16_t scd4x_measure_single_shot_rht_only() {
    int16_t error;
    uint8_t buffer[2];
    uint16_t offset = 0;
    offset = sensirion_i2c_add_command_to_buffer(&buffer[0], offset, 0x2196);

    error = sensirion_i2c_write_data(SCD4X_I2C_ADDRESS, &buffer[0], offset);
    if (error) {
        return error;
    }
    sensirion_i2c_hal_sleep_usec(50000);
    return NO_ERROR;
}

int16_t scd4x_power_down() {
    int16_t error;
    uint8_t buffer[2];
    uint16_t offset = 0;
    offset = sensirion_i2c_add_command_to_buffer(&buffer[0], offset, 0x36E0);

    error = sensirion_i2c_write_data(SCD4X_I2C_ADDRESS, &buffer[0], offset);
    if (error) {
        return error;
    }
    sensirion_i2c_hal_sleep_usec(1000);
    return NO_ERROR;
}

int16_t scd4x_wake_up() {
    uint8_t buffer[2];
    uint16_t offset = 0;
    offset = sensirion_i2c_add_command_to_buffer(&buffer[0], offset, 0x36F6);

    // Sensor does not acknowledge the wake-up call, error is ignored
    (void)sensirion_i2c_write_data(SCD4X_I2C_ADDRESS, &buffer[0], offset);
    sensirion_i2c_hal_sleep_usec(20000);
    return NO_ERROR;
}
```

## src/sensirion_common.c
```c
#include "sensirion_common.h"
#include "sensirion_config.h"

uint16_t sensirion_common_bytes_to_uint16_t(const uint8_t* bytes) {
    return (uint16_t)bytes[0] << 8 | (uint16_t)bytes[1];
}

uint32_t sensirion_common_bytes_to_uint32_t(const uint8_t* bytes) {
    return (uint32_t)bytes[0] << 24 | (uint32_t)bytes[1] << 16 |
           (uint32_t)bytes[2] << 8 | (uint32_t)bytes[3];
}

int16_t sensirion_common_bytes_to_int16_t(const uint8_t* bytes) {
    return (int16_t)sensirion_common_bytes_to_uint16_t(bytes);
}

int32_t sensirion_common_bytes_to_int32_t(const uint8_t* bytes) {
    return (int32_t)sensirion_common_bytes_to_uint32_t(bytes);
}

float sensirion_common_bytes_to_float(const uint8_t* bytes) {
    union {
        uint32_t u32_value;
        float float32;
    } tmp;

    tmp.u32_value = sensirion_common_bytes_to_uint32_t(bytes);
    return tmp.float32;
}

void sensirion_common_uint32_t_to_bytes(const uint32_t value, uint8_t* bytes) {
    bytes[0] = value >> 24;
    bytes[1] = value >> 16;
    bytes[2] = value >> 8;
    bytes[3] = value;
}

void sensirion_common_uint16_t_to_bytes(const uint16_t value, uint8_t* bytes) {
    bytes[0] = value >> 8;
    bytes[1] = value;
}

void sensirion_common_int32_t_to_bytes(const int32_t value, uint8_t* bytes) {
    bytes[0] = value >> 24;
    bytes[1] = value >> 16;
    bytes[2] = value >> 8;
    bytes[3] = value;
}

void sensirion_common_int16_t_to_bytes(const int16_t value, uint8_t* bytes) {
    bytes[0] = value >> 8;
    bytes[1] = value;
}

void sensirion_common_float_to_bytes(const float value, uint8_t* bytes) {
    union {
        uint32_t u32_value;
        float float32;
    } tmp;
    tmp.float32 = value;
    sensirion_common_uint32_t_to_bytes(tmp.u32_value, bytes);
}

void sensirion_common_copy_bytes(const uint8_t* source, uint8_t* destination,
                                 uint16_t data_length) {
    uint16_t i;
    for (i = 0; i < data_length; i++) {
        destination[i] = source[i];
    }
}
```

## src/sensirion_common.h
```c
#ifndef SENSIRION_COMMON_H
#define SENSIRION_COMMON_H

#include "sensirion_config.h"

#ifdef __cplusplus
extern "C" {
#endif

#define NO_ERROR 0
#define NOT_IMPLEMENTED_ERROR 31

#ifndef ARRAY_SIZE
#define ARRAY_SIZE(x) (sizeof(x) / sizeof(*(x)))
#endif

#define SENSIRION_COMMAND_SIZE 2
#define SENSIRION_WORD_SIZE 2
#define SENSIRION_NUM_WORDS(x) (sizeof(x) / SENSIRION_WORD_SIZE)
#define SENSIRION_MAX_BUFFER_WORDS 32

/**
 * sensirion_common_bytes_to_int16_t() - Convert an array of bytes to an int16_t
 *
 * Convert an array of bytes received from the sensor in big-endian/MSB-first
 * format to an int16_t value in the correct system-endianness.
 *
 * @param bytes An array of at least two bytes (MSB first)
 * @return      The byte array represented as int16_t
 */
int16_t sensirion_common_bytes_to_int16_t(const uint8_t* bytes);

/**
 * sensirion_common_bytes_to_int32_t() - Convert an array of bytes to an int32_t
 *
 * Convert an array of bytes received from the sensor in big-endian/MSB-first
 * format to an int32_t value in the correct system-endianness.
 *
 * @param bytes An array of at least four bytes (MSB first)
 * @return      The byte array represented as int32_t
 */
int32_t sensirion_common_bytes_to_int32_t(const uint8_t* bytes);

/**
 * sensirion_common_bytes_to_uint16_t() - Convert an array of bytes to an
 * uint16_t
 *
 * Convert an array of bytes received from the sensor in big-endian/MSB-first
 * format to an uint16_t value in the correct system-endianness.
 *
 * @param bytes An array of at least two bytes (MSB first)
 * @return      The byte array represented as uint16_t
 */
uint16_t sensirion_common_bytes_to_uint16_t(const uint8_t* bytes);

/**
 * sensirion_common_bytes_to_uint32_t() - Convert an array of bytes to an
 * uint32_t
 *
 * Convert an array of bytes received from the sensor in big-endian/MSB-first
 * format to an uint32_t value in the correct system-endianness.
 *
 * @param bytes An array of at least four bytes (MSB first)
 * @return      The byte array represented as uint32_t
 */
uint32_t sensirion_common_bytes_to_uint32_t(const uint8_t* bytes);

/**
 * sensirion_common_bytes_to_float() - Convert an array of bytes to a float
 *
 * Convert an array of bytes received from the sensor in big-endian/MSB-first
 * format to an float value in the correct system-endianness.
 *
 * @param bytes An array of at least four bytes (MSB first)
 * @return      The byte array represented as float
 */
float sensirion_common_bytes_to_float(const uint8_t* bytes);

/**
 * sensirion_common_uint32_t_to_bytes() - Convert an uint32_t to an array of
 * bytes
 *
 * Convert an uint32_t value in system-endianness to big-endian/MBS-first
 * format to send to the sensor.
 *
 * @param value Value to convert
 * @param bytes An array of at least four bytes
 */
void sensirion_common_uint32_t_to_bytes(const uint32_t value, uint8_t* bytes);

/**
 * sensirion_common_uint16_t_to_bytes() - Convert an uint16_t to an array of
 * bytes
 *
 * Convert an uint16_t value in system-endianness to big-endian/MBS-first
 * format to send to the sensor.
 *
 * @param value Value to convert
 * @param bytes An array of at least two bytes
 */
void sensirion_common_uint16_t_to_bytes(const uint16_t value, uint8_t* bytes);

/**
 * sensirion_common_int32_t_to_bytes() - Convert an int32_t to an array of bytes
 *
 * Convert an int32_t value in system-endianness to big-endian/MBS-first
 * format to send to the sensor.
 *
 * @param value Value to convert
 * @param bytes An array of at least four bytes
 */
void sensirion_common_int32_t_to_bytes(const int32_t value, uint8_t* bytes);

/**
 * sensirion_common_int16_t_to_bytes() - Convert an int16_t to an array of bytes
 *
 * Convert an int16_t value in system-endianness to big-endian/MBS-first
 * format to send to the sensor.
 *
 * @param value Value to convert
 * @param bytes An array of at least two bytes
 */
void sensirion_common_int16_t_to_bytes(const int16_t value, uint8_t* bytes);

/**
 * sensirion_common_float_to_bytes() - Convert an float to an array of bytes
 *
 * Convert an float value in system-endianness to big-endian/MBS-first
 * format to send to the sensor.
 *
 * @param value Value to convert
 * @param bytes An array of at least four bytes
 */
void sensirion_common_float_to_bytes(const float value, uint8_t* bytes);

/**
 * sensirion_common_copy_bytes() - Copy bytes from one array to the other.
 *
 * @param source      Array of bytes to be copied.
 * @param destination Array of bytes to be copied to.
 * @param data_length Number of bytes to copy.
 */
void sensirion_common_copy_bytes(const uint8_t* source, uint8_t* destination,
                                 uint16_t data_length);

#ifdef __cplusplus
}
#endif

#endif /* SENSIRION_COMMON_H */
```

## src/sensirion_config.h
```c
#ifndef SENSIRION_CONFIG_H
#define SENSIRION_CONFIG_H

/**
 * Zephyr includes
 * - NULL
 * - (probably) all types of int below
*/

#include <zephyr/kernel.h>

/**
 * Include NULL and malloc.
 */
#include <stdlib.h>

/**
 * Include Logging.
*/
#include <zephyr/logging/log.h>

#ifndef __cplusplus

#endif /* __cplusplus */

#endif /* SENSIRION_CONFIG_H */
```
